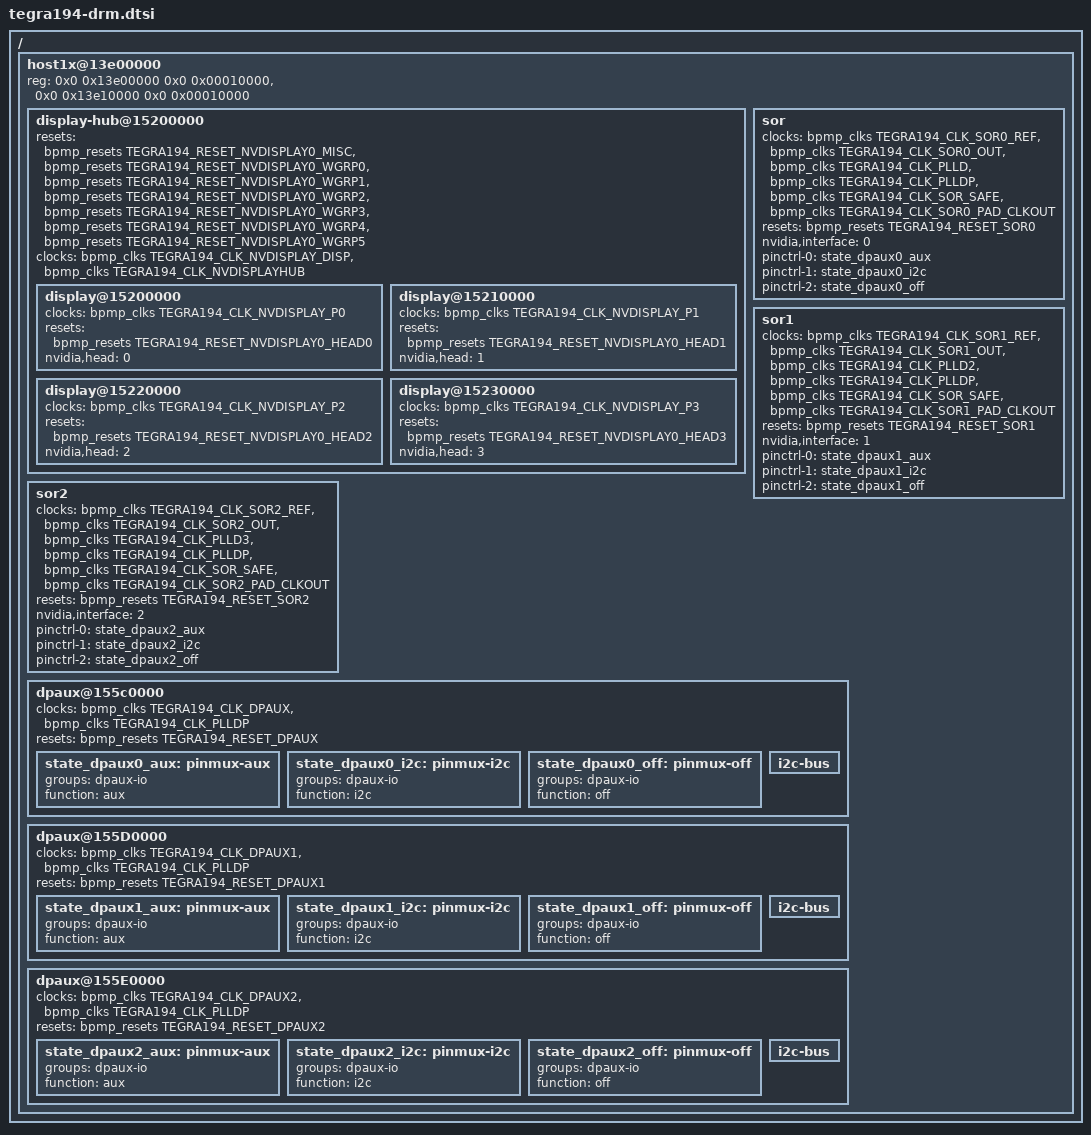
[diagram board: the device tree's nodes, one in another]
/*
 * Copyright (C) 2022 The LineageOS Project
 *
 * This program is free software; you can redistribute it and/or modify it
 * under the terms and conditions of the GNU General Public License,
 * version 2, as published by the Free Software Foundation.
 *
 * This program is distributed in the hope it will be useful, but WITHOUT
 * ANY WARRANTY; without even the implied warranty of MERCHANTABILITY or
 * FITNESS FOR A PARTICULAR PURPOSE.  See the GNU General Public License for
 * more details.
 *
 * You should have received a copy of the GNU General Public License
 * along with this program.  If not, see <http://www.gnu.org/licenses/>.
 */

/*
 * tegra194-drm.dtsi: Platform common SoC specific DTSI file for tegra-drm
 */

/ {

	host1x@13e00000 {
		reg = <0x0 0x13e00000 0x0 0x00010000>,
		      <0x0 0x13e10000 0x0 0x00010000>;
		reg-names = "hypervisor", "vm";
		reset-names = "host1x";
		interrupt-names = "syncpt", "host1x";

		display-hub@15200000 {
			resets = <&bpmp_resets TEGRA194_RESET_NVDISPLAY0_MISC>,
				 <&bpmp_resets TEGRA194_RESET_NVDISPLAY0_WGRP0>,
				 <&bpmp_resets TEGRA194_RESET_NVDISPLAY0_WGRP1>,
				 <&bpmp_resets TEGRA194_RESET_NVDISPLAY0_WGRP2>,
				 <&bpmp_resets TEGRA194_RESET_NVDISPLAY0_WGRP3>,
				 <&bpmp_resets TEGRA194_RESET_NVDISPLAY0_WGRP4>,
				 <&bpmp_resets TEGRA194_RESET_NVDISPLAY0_WGRP5>;
			reset-names = "misc", "wgrp0", "wgrp1", "wgrp2",
				      "wgrp3", "wgrp4", "wgrp5";
			clocks = <&bpmp_clks TEGRA194_CLK_NVDISPLAY_DISP>,
				 <&bpmp_clks TEGRA194_CLK_NVDISPLAYHUB>;
			clock-names = "disp", "hub";

			display@15200000 {
				clocks = <&bpmp_clks TEGRA194_CLK_NVDISPLAY_P0>;
				clock-names = "dc";
				resets = <&bpmp_resets TEGRA194_RESET_NVDISPLAY0_HEAD0>;
				reset-names = "dc";
				nvidia,head = <0>;
			};

			display@15210000 {
				clocks = <&bpmp_clks TEGRA194_CLK_NVDISPLAY_P1>;
				clock-names = "dc";
				resets = <&bpmp_resets TEGRA194_RESET_NVDISPLAY0_HEAD1>;
				reset-names = "dc";
				nvidia,head = <1>;
			};

			display@15220000 {
				clocks = <&bpmp_clks TEGRA194_CLK_NVDISPLAY_P2>;
				clock-names = "dc";
				resets = <&bpmp_resets TEGRA194_RESET_NVDISPLAY0_HEAD2>;
				reset-names = "dc";
				nvidia,head = <2>;
			};

			display@15230000 {
				clocks = <&bpmp_clks TEGRA194_CLK_NVDISPLAY_P3>;
				clock-names = "dc";
				resets = <&bpmp_resets TEGRA194_RESET_NVDISPLAY0_HEAD3>;
				reset-names = "dc";
				nvidia,head = <3>;
			};
		};

		sor {
			clocks = <&bpmp_clks TEGRA194_CLK_SOR0_REF>,
				 <&bpmp_clks TEGRA194_CLK_SOR0_OUT>,
				 <&bpmp_clks TEGRA194_CLK_PLLD>,
				 <&bpmp_clks TEGRA194_CLK_PLLDP>,
				 <&bpmp_clks TEGRA194_CLK_SOR_SAFE>,
				 <&bpmp_clks TEGRA194_CLK_SOR0_PAD_CLKOUT>;
			clock-names = "sor", "out", "parent", "dp", "safe",
				      "pad";
			resets = <&bpmp_resets TEGRA194_RESET_SOR0>;
			reset-names = "sor";
			nvidia,interface = <0>;
			/delete-property/ nvidia,dpaux;
			pinctrl-0 = <&state_dpaux0_aux>;
			pinctrl-1 = <&state_dpaux0_i2c>;
			pinctrl-2 = <&state_dpaux0_off>;
			pinctrl-names = "aux", "i2c", "off";
		};

		sor1 {
			clocks = <&bpmp_clks TEGRA194_CLK_SOR1_REF>,
				 <&bpmp_clks TEGRA194_CLK_SOR1_OUT>,
				 <&bpmp_clks TEGRA194_CLK_PLLD2>,
				 <&bpmp_clks TEGRA194_CLK_PLLDP>,
				 <&bpmp_clks TEGRA194_CLK_SOR_SAFE>,
				 <&bpmp_clks TEGRA194_CLK_SOR1_PAD_CLKOUT>;
			clock-names = "sor", "out", "parent", "dp", "safe",
				      "pad";
			resets = <&bpmp_resets TEGRA194_RESET_SOR1>;
			reset-names = "sor";
			nvidia,interface = <1>;
			/delete-property/ nvidia,dpaux;
			pinctrl-0 = <&state_dpaux1_aux>;
			pinctrl-1 = <&state_dpaux1_i2c>;
			pinctrl-2 = <&state_dpaux1_off>;
			pinctrl-names = "aux", "i2c", "off";
		};

		sor2 {
			clocks = <&bpmp_clks TEGRA194_CLK_SOR2_REF>,
				 <&bpmp_clks TEGRA194_CLK_SOR2_OUT>,
				 <&bpmp_clks TEGRA194_CLK_PLLD3>,
				 <&bpmp_clks TEGRA194_CLK_PLLDP>,
				 <&bpmp_clks TEGRA194_CLK_SOR_SAFE>,
				 <&bpmp_clks TEGRA194_CLK_SOR2_PAD_CLKOUT>;
			clock-names = "sor", "out", "parent", "dp", "safe",
				      "pad";
			resets = <&bpmp_resets TEGRA194_RESET_SOR2>;
			reset-names = "sor";
			nvidia,interface = <2>;
			/delete-property/ nvidia,dpaux;
			pinctrl-0 = <&state_dpaux2_aux>;
			pinctrl-1 = <&state_dpaux2_i2c>;
			pinctrl-2 = <&state_dpaux2_off>;
			pinctrl-names = "aux", "i2c", "off";
		};

		dpaux@155c0000 {
			clocks = <&bpmp_clks TEGRA194_CLK_DPAUX>,
				 <&bpmp_clks TEGRA194_CLK_PLLDP>;
			clock-names = "dpaux", "parent";
			resets = <&bpmp_resets TEGRA194_RESET_DPAUX>;
			reset-names = "dpaux";

			state_dpaux0_aux: pinmux-aux {
				groups = "dpaux-io";
				function = "aux";
			};

			state_dpaux0_i2c: pinmux-i2c {
				groups = "dpaux-io";
				function = "i2c";
			};

			state_dpaux0_off: pinmux-off {
				groups = "dpaux-io";
				function = "off";
			};

			i2c-bus {
				#address-cells = <1>;
				#size-cells = <0>;
			};
		};

		dpaux@155D0000 {
			clocks = <&bpmp_clks TEGRA194_CLK_DPAUX1>,
				 <&bpmp_clks TEGRA194_CLK_PLLDP>;
			clock-names = "dpaux", "parent";
			resets = <&bpmp_resets TEGRA194_RESET_DPAUX1>;
			reset-names = "dpaux";

			state_dpaux1_aux: pinmux-aux {
				groups = "dpaux-io";
				function = "aux";
			};

			state_dpaux1_i2c: pinmux-i2c {
				groups = "dpaux-io";
				function = "i2c";
			};

			state_dpaux1_off: pinmux-off {
				groups = "dpaux-io";
				function = "off";
			};

			i2c-bus {
				#address-cells = <1>;
				#size-cells = <0>;
			};
		};

		dpaux@155E0000 {
			clocks = <&bpmp_clks TEGRA194_CLK_DPAUX2>,
				 <&bpmp_clks TEGRA194_CLK_PLLDP>;
			clock-names = "dpaux", "parent";
			resets = <&bpmp_resets TEGRA194_RESET_DPAUX2>;
			reset-names = "dpaux";

			state_dpaux2_aux: pinmux-aux {
				groups = "dpaux-io";
				function = "aux";
			};

			state_dpaux2_i2c: pinmux-i2c {
				groups = "dpaux-io";
				function = "i2c";
			};

			state_dpaux2_off: pinmux-off {
				groups = "dpaux-io";
				function = "off";
			};

			i2c-bus {
				#address-cells = <1>;
				#size-cells = <0>;
			};
		};
	};
};
